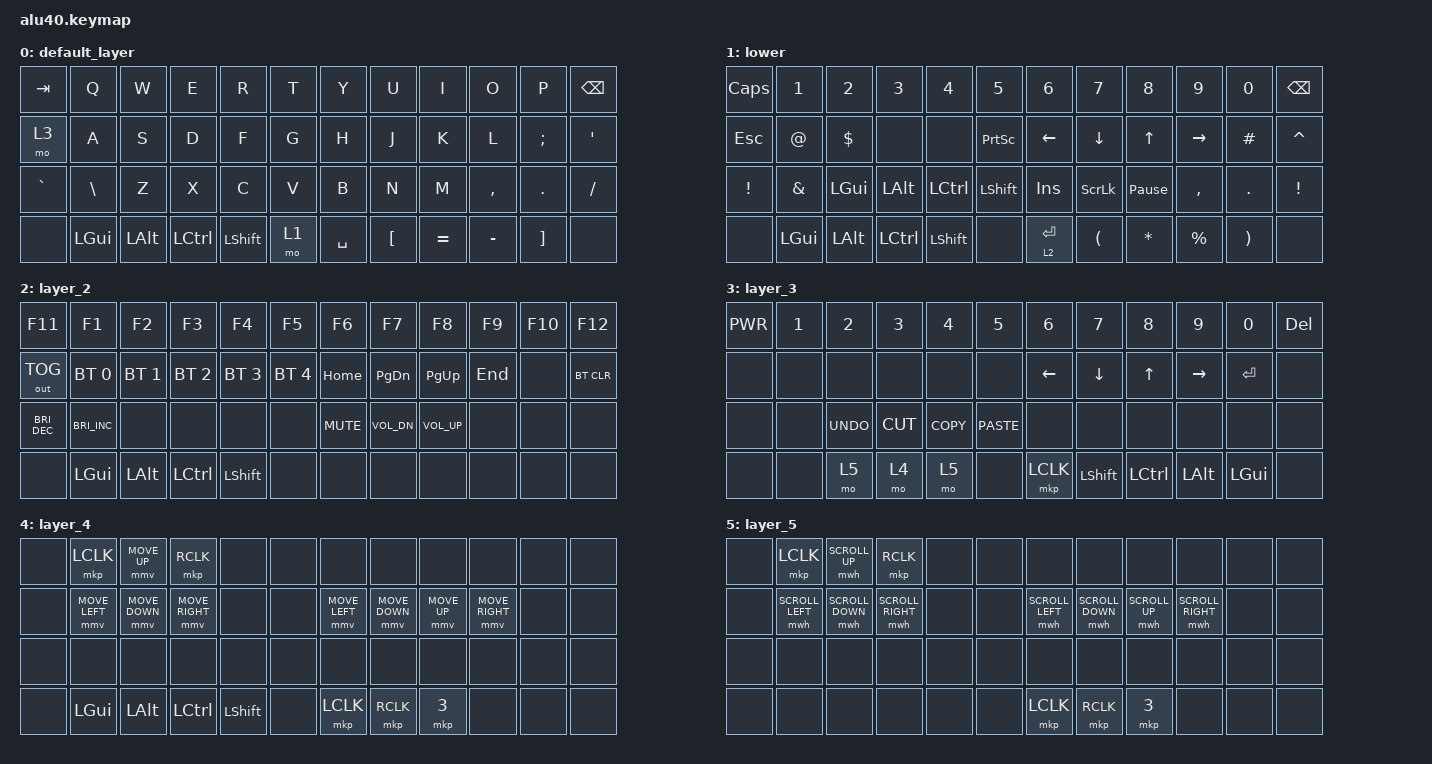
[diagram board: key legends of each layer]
/*
 * Copyright (c) 2022 The ZMK Contributors
 *
 * SPDX-License-Identifier: MIT
 */

#include <behaviors.dtsi>
#include <dt-bindings/zmk/bt.h>
#include <dt-bindings/zmk/keys.h>
#include <dt-bindings/zmk/outputs.h>
#include <dt-bindings/zmk/pointing.h>

#define U_MOUSE_MOVE_EXPONENT 2
#define U_MOUSE_MOVE_DELAY 0

#define U_MOUSE_SCROLL_EXPONENT 0
#define U_MOUSE_SCROLL_DELAY 0

#undef MOVE_UP
#undef MOVE_DOWN
#undef MOVE_LEFT
#undef MOVE_RIGHT
#define MOVE_UP MOVE_Y(-1100)
#define MOVE_DOWN MOVE_Y(1100)
#define MOVE_LEFT MOVE_X(-1300)
#define MOVE_RIGHT MOVE_X(1300)

#undef SCROLL_UP
#undef SCROLL_DOWN
#undef SCROLL_LEFT
#undef SCROLL_RIGHT
#define SCROLL_UP SCROLL_Y(11)
#define SCROLL_DOWN SCROLL_Y(-11)
#define SCROLL_LEFT SCROLL_X(-13)
#define SCROLL_RIGHT SCROLL_X(13)

&mmv {
    time-to-max-speed-ms=<160>;
    acceleration-exponent=<2>;
};

&mwh {
    time-to-max-speed-ms=<1>;
    acceleration-exponent=<2>;
};


/ {
    keymap {
        compatible = "zmk,keymap";

        default_layer {
            // -----------------------------------------------------------------------------------------
            // | ESC/~ |  Q   |  W   |  E   |  R   |  T   |   Y   |  U    |  I   |  O   |   P   | BSPC  |
            // | TAB   |  A   |  S   |  D   |  F   |  G   |   H   |  J    |  K   |  L   |   ;   |  '    |
            // | SHIFT |  Z   |  X   |  C   |  V   |  B   |   N   |  M    |  ,   |  .   |   /   |RET/SFT|
            // | PLAY  | LCTL | LALT | LGUI | LOWR |     SPACE    |  RAIS | LARW | UARW | DARW  |  RARW |

            bindings = <
&kp TAB    &kp Q         &kp W      &kp E    &kp R     &kp T &kp Y     &kp U            &kp I     &kp O      &kp P             &kp BSPC
&mo 3      &kp A         &kp S      &kp D    &kp F     &kp G &kp H     &kp J            &kp K     &kp L      &kp SEMI          &kp SQT
&kp GRAVE  &kp BACKSLASH &kp Z      &kp X    &kp C     &kp V &kp B     &kp N            &kp M     &kp COMMA  &kp PERIOD        &kp SLASH
&none      &kp LGUI      &kp LALT  &kp LCTRL &kp LSHFT &mo 1 &kp SPACE &kp LEFT_BRACKET &kp EQUAL &kp MINUS  &kp RIGHT_BRACKET &none
            >;
        };

        lower {
            bindings = <
&kp CAPS        &kp N1        &kp N2      &kp N3   &kp N4    &kp N5          &kp N6     &kp N7               &kp N8          &kp N9      &kp N0                 &kp BACKSPACE
&kp ESCAPE      &kp AT_SIGN   &kp DOLLAR &none  &none &kp PRINTSCREEN &kp LEFT   &kp DOWN             &kp UP          &kp RIGHT   &kp HASH               &kp CARET
&kp EXCLAMATION &kp AMPERSAND &kp LGUI   &kp LALT &kp LCTRL  &kp LSHFT       &kp INSERT &kp SCROLLLOCK       &kp PAUSE_BREAK &kp COMMA   &kp DOT                &kp EXCLAMATION
&none           &kp LGUI      &kp LALT  &kp LCTRL  &kp LSHFT  &none          &lt 2 RET  &kp LEFT_PARENTHESIS &kp ASTERISK    &kp PERCENT &kp RIGHT_PARENTHESIS  &none
            >;
        };

        layer_2 {
            bindings = <
&kp F11        &kp F1  &kp F2  &kp F3 &kp F4 &kp F5 &kp F6         &kp F7         &kp F8       &kp F9          &kp F10      &kp F12
&out OUT_TOG &bt BT_SEL 0 &bt BT_SEL 1  &bt BT_SEL 2 &bt BT_SEL 3 &bt BT_SEL 4   &kp HOME     &kp PAGE_DOWN &kp PAGE_UP  &kp END      &none        &bt BT_CLR
&kp C_BRI_DEC &kp C_BRI_INC  &none  &none &none &none &kp C_MUTE &kp C_VOL_DN &kp C_VOL_UP  &none  &none &none    
&none        &kp LGUI &kp LALT     &kp LCTRL      &kp LSHFT    &none        &none        &none         &none        &none        &none         &none
            >;
        };

        layer_3 {
            bindings = <
&kp C_PWR &kp N1 &kp N2     &kp N3    &kp N4     &kp N5      &kp N6    &kp N7    &kp N8   &kp N9    &kp N0   &kp DELETE
&none &none  &none      &none     &none      &none       &kp LEFT  &kp DOWN  &kp UP   &kp RIGHT &kp RET    &none
&none &none  &kp K_UNDO &kp K_CUT &kp K_COPY &kp K_PASTE &none     &none     &none    &none     &none    &none
&none &none  &mo 5      &mo 4     &mo 5      &none   &mkp LCLK &kp LSHFT &kp LCTRL &kp LALT &kp LGUI &none
            >;
        };

        layer_4 {
            bindings = <
&none &mkp LCLK  &mmv MOVE_UP  &mkp RCLK &none &none &none        &none &none &none &none   &none
&none &mmv MOVE_LEFT  &mmv MOVE_DOWN  &mmv MOVE_RIGHT  &none  &none  &mmv MOVE_LEFT &mmv MOVE_DOWN &mmv MOVE_UP &mmv MOVE_RIGHT &none   &none
&none &none   &none   &none  &none  &none &none &none   &none   &none  &none          &none
&none &kp LGUI   &kp LALT   &kp LCTRL  &kp LSHFT  &none  &mkp LCLK      &mkp RCLK      &mkp 3       &none &none   &none
            >;
        };

        layer_5 {
            bindings = <
&none  &mkp LCLK  &mwh SCROLL_UP  &mkp RCLK  &none  &none        &none            &none            &none          &none             &none  &none
&none  &mwh SCROLL_LEFT  &mwh SCROLL_DOWN  &mwh SCROLL_RIGHT  &none  &none        &mwh SCROLL_LEFT &mwh SCROLL_DOWN &mwh SCROLL_UP &mwh SCROLL_RIGHT &none  &none
&none  &none  &none  &none  &none  &none        &none            &none            &none          &none             &none  &none
&none  &none  &none  &none  &none  &none        &mkp LCLK        &mkp RCLK        &mkp 3         &none             &none  &none
            >;
        };
    };
};
